AUTOSAR XML (schema 4-2-2)
package /AUTOLIV
  impl type au8MergedBuckleStatusType: category=ARRAY
    element elem_au8MergedBuckleStatusType_Appl: category=VALUE, array-size=6, array-size-semantics=FIXED-SIZE, base-type=uint8, data-constr=DataConstr_impl_u8GurtschlossStatusReihe2BFType_Appl
package /AUTOLIV/SoftwareCompositions/S32K_eCS_ECU_ApplicationComp
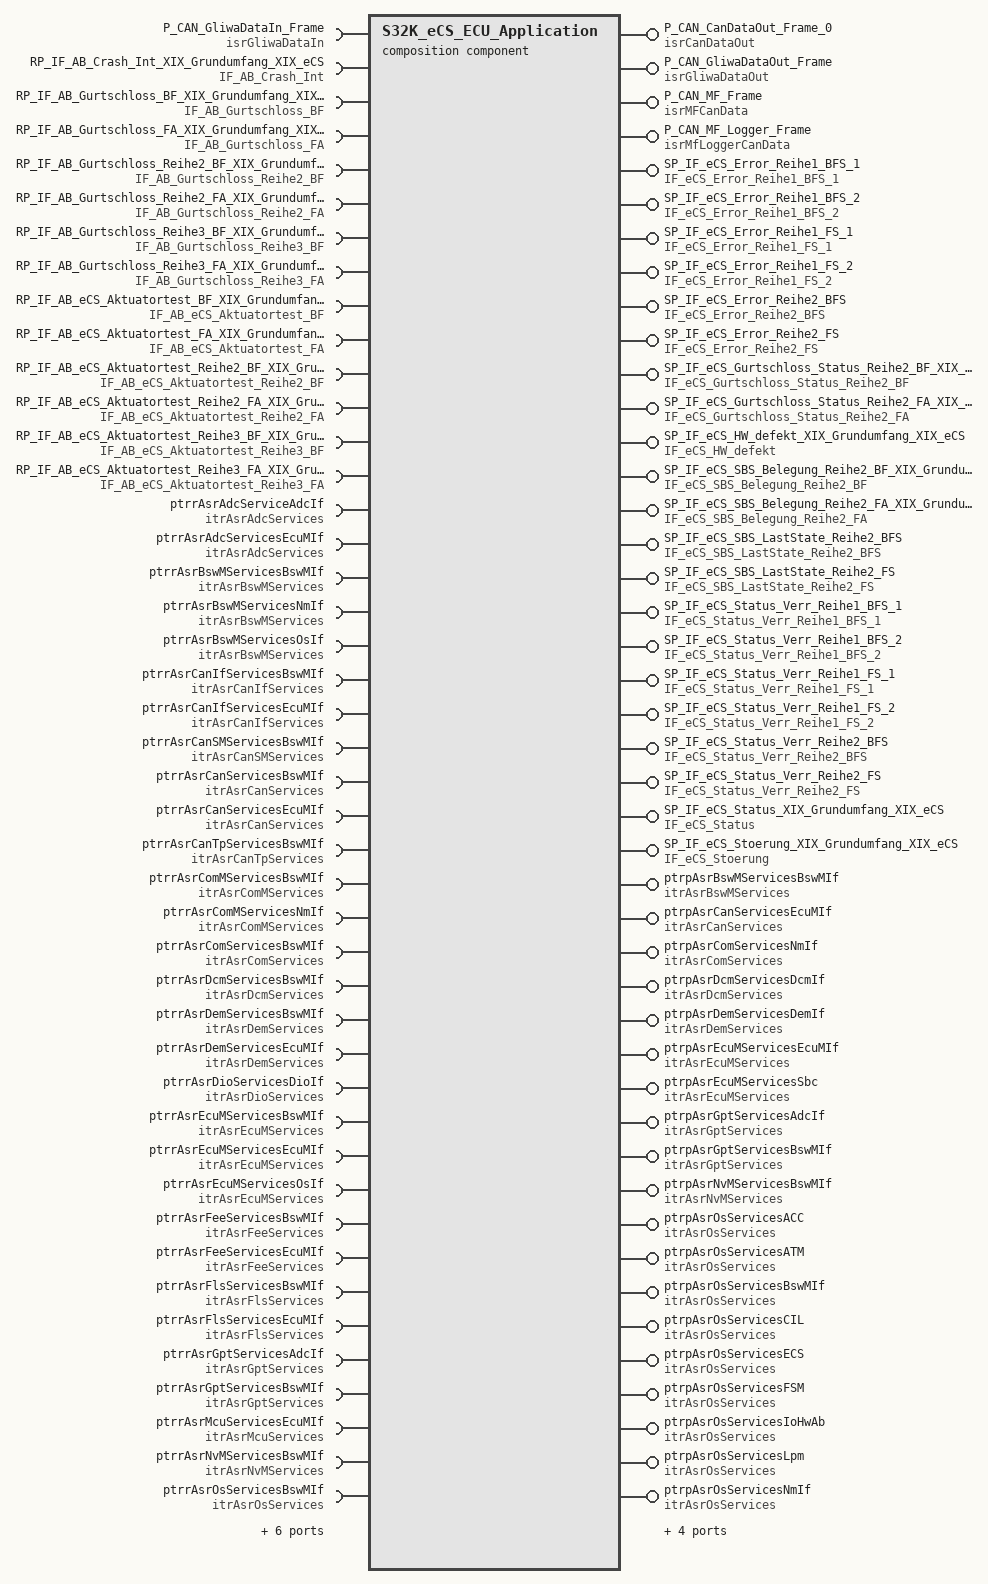
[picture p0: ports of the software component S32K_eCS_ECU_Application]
  composition sw component type S32K_eCS_ECU_Application
    provide port P_CAN_CanDataOut_Frame_0: provided-interface=isrCanDataOut
    require port P_CAN_GliwaDataIn_Frame: required-interface=isrGliwaDataIn
    provide port P_CAN_GliwaDataOut_Frame: provided-interface=isrGliwaDataOut
    provide port P_CAN_MF_Frame: provided-interface=isrMFCanData
    provide port P_CAN_MF_Logger_Frame: provided-interface=isrMfLoggerCanData
    13 x require port:
      RP_IF_AB_Crash_Int_XIX_Grundumfang_XIX_eCS: required-interface=IF_AB_Crash_Int
      RP_IF_AB_Gurtschloss_BF_XIX_Grundumfang_XIX_eCS: required-interface=IF_AB_Gurtschloss_BF
      RP_IF_AB_Gurtschloss_FA_XIX_Grundumfang_XIX_eCS: required-interface=IF_AB_Gurtschloss_FA
      RP_IF_AB_Gurtschloss_Reihe2_BF_XIX_Grundumfang_XIX_eCS: required-interface=IF_AB_Gurtschloss_Reihe2_BF
      RP_IF_AB_Gurtschloss_Reihe2_FA_XIX_Grundumfang_XIX_eCS: required-interface=IF_AB_Gurtschloss_Reihe2_FA
      RP_IF_AB_Gurtschloss_Reihe3_BF_XIX_Grundumfang_XIX_eCS: required-interface=IF_AB_Gurtschloss_Reihe3_BF
      RP_IF_AB_Gurtschloss_Reihe3_FA_XIX_Grundumfang_XIX_eCS: required-interface=IF_AB_Gurtschloss_Reihe3_FA
      RP_IF_AB_eCS_Aktuatortest_BF_XIX_Grundumfang_XIX_eCS: required-interface=IF_AB_eCS_Aktuatortest_BF
      RP_IF_AB_eCS_Aktuatortest_FA_XIX_Grundumfang_XIX_eCS: required-interface=IF_AB_eCS_Aktuatortest_FA
      RP_IF_AB_eCS_Aktuatortest_Reihe2_BF_XIX_Grundumfang_XIX_eCS: required-interface=IF_AB_eCS_Aktuatortest_Reihe2_BF
      RP_IF_AB_eCS_Aktuatortest_Reihe2_FA_XIX_Grundumfang_XIX_eCS: required-interface=IF_AB_eCS_Aktuatortest_Reihe2_FA
      RP_IF_AB_eCS_Aktuatortest_Reihe3_BF_XIX_Grundumfang_XIX_eCS: required-interface=IF_AB_eCS_Aktuatortest_Reihe3_BF
      RP_IF_AB_eCS_Aktuatortest_Reihe3_FA_XIX_Grundumfang_XIX_eCS: required-interface=IF_AB_eCS_Aktuatortest_Reihe3_FA
    44 x provide port:
      SP_IF_eCS_Error_Reihe1_BFS_1: provided-interface=IF_eCS_Error_Reihe1_BFS_1
      SP_IF_eCS_Error_Reihe1_BFS_2: provided-interface=IF_eCS_Error_Reihe1_BFS_2
      SP_IF_eCS_Error_Reihe1_FS_1: provided-interface=IF_eCS_Error_Reihe1_FS_1
      SP_IF_eCS_Error_Reihe1_FS_2: provided-interface=IF_eCS_Error_Reihe1_FS_2
      SP_IF_eCS_Error_Reihe2_BFS: provided-interface=IF_eCS_Error_Reihe2_BFS
      SP_IF_eCS_Error_Reihe2_FS: provided-interface=IF_eCS_Error_Reihe2_FS
      SP_IF_eCS_Gurtschloss_Status_Reihe2_BF_XIX_Grundumfang_XIX_eCS: provided-interface=IF_eCS_Gurtschloss_Status_Reihe2_BF
      SP_IF_eCS_Gurtschloss_Status_Reihe2_FA_XIX_Grundumfang_XIX_eCS: provided-interface=IF_eCS_Gurtschloss_Status_Reihe2_FA
      SP_IF_eCS_HW_defekt_XIX_Grundumfang_XIX_eCS: provided-interface=IF_eCS_HW_defekt
      SP_IF_eCS_SBS_Belegung_Reihe2_BF_XIX_Grundumfang_XIX_eCS: provided-interface=IF_eCS_SBS_Belegung_Reihe2_BF
      SP_IF_eCS_SBS_Belegung_Reihe2_FA_XIX_Grundumfang_XIX_eCS: provided-interface=IF_eCS_SBS_Belegung_Reihe2_FA
      SP_IF_eCS_SBS_LastState_Reihe2_BFS: provided-interface=IF_eCS_SBS_LastState_Reihe2_BFS
      SP_IF_eCS_SBS_LastState_Reihe2_FS: provided-interface=IF_eCS_SBS_LastState_Reihe2_FS
      SP_IF_eCS_Status_Verr_Reihe1_BFS_1: provided-interface=IF_eCS_Status_Verr_Reihe1_BFS_1
      SP_IF_eCS_Status_Verr_Reihe1_BFS_2: provided-interface=IF_eCS_Status_Verr_Reihe1_BFS_2
      SP_IF_eCS_Status_Verr_Reihe1_FS_1: provided-interface=IF_eCS_Status_Verr_Reihe1_FS_1
      SP_IF_eCS_Status_Verr_Reihe1_FS_2: provided-interface=IF_eCS_Status_Verr_Reihe1_FS_2
      SP_IF_eCS_Status_Verr_Reihe2_BFS: provided-interface=IF_eCS_Status_Verr_Reihe2_BFS
      SP_IF_eCS_Status_Verr_Reihe2_FS: provided-interface=IF_eCS_Status_Verr_Reihe2_FS
      SP_IF_eCS_Status_XIX_Grundumfang_XIX_eCS: provided-interface=IF_eCS_Status
      SP_IF_eCS_Stoerung_XIX_Grundumfang_XIX_eCS: provided-interface=IF_eCS_Stoerung
      ptrpAsrBswMServicesBswMIf: provided-interface=itrAsrBswMServices
      ptrpAsrCanServicesEcuMIf: provided-interface=itrAsrCanServices
      ptrpAsrComServicesNmIf: provided-interface=itrAsrComServices
      ptrpAsrDcmServicesDcmIf: provided-interface=itrAsrDcmServices
      ptrpAsrDemServicesDemIf: provided-interface=itrAsrDemServices
      ptrpAsrEcuMServicesEcuMIf: provided-interface=itrAsrEcuMServices
      ptrpAsrEcuMServicesSbc: provided-interface=itrAsrEcuMServices
      ptrpAsrGptServicesAdcIf: provided-interface=itrAsrGptServices
      ptrpAsrGptServicesBswMIf: provided-interface=itrAsrGptServices
      ptrpAsrNvMServicesBswMIf: provided-interface=itrAsrNvMServices
      ptrpAsrOsServicesACC: provided-interface=itrAsrOsServices
      ptrpAsrOsServicesATM: provided-interface=itrAsrOsServices
      ptrpAsrOsServicesBswMIf: provided-interface=itrAsrOsServices
      ptrpAsrOsServicesCIL: provided-interface=itrAsrOsServices
      ptrpAsrOsServicesECS: provided-interface=itrAsrOsServices
      ptrpAsrOsServicesFSM: provided-interface=itrAsrOsServices
      ptrpAsrOsServicesIoHwAb: provided-interface=itrAsrOsServices
      ptrpAsrOsServicesLpm: provided-interface=itrAsrOsServices
      ptrpAsrOsServicesNmIf: provided-interface=itrAsrOsServices
      ptrpAsrOsServicesOsIf: provided-interface=itrAsrOsServices
      ptrpAsrOsServicesSAD: provided-interface=itrAsrOsServices
      ptrpAsrOsServicesSBC: provided-interface=itrAsrOsServices
      ptrpAsrOsServicesSTM: provided-interface=itrAsrOsServices
    36 x require port:
      ptrrAsrAdcServiceAdcIf: required-interface=itrAsrAdcServices
      ptrrAsrAdcServicesEcuMIf: required-interface=itrAsrAdcServices
      ptrrAsrBswMServicesBswMIf: required-interface=itrAsrBswMServices
      ptrrAsrBswMServicesNmIf: required-interface=itrAsrBswMServices
      ptrrAsrBswMServicesOsIf: required-interface=itrAsrBswMServices
      ptrrAsrCanIfServicesBswMIf: required-interface=itrAsrCanIfServices
      ptrrAsrCanIfServicesEcuMIf: required-interface=itrAsrCanIfServices
      ptrrAsrCanSMServicesBswMIf: required-interface=itrAsrCanSMServices
      ptrrAsrCanServicesBswMIf: required-interface=itrAsrCanServices
      ptrrAsrCanServicesEcuMIf: required-interface=itrAsrCanServices
      ptrrAsrCanTpServicesBswMIf: required-interface=itrAsrCanTpServices
      ptrrAsrComMServicesBswMIf: required-interface=itrAsrComMServices
      ptrrAsrComMServicesNmIf: required-interface=itrAsrComMServices
      ptrrAsrComServicesBswMIf: required-interface=itrAsrComServices
      ptrrAsrDcmServicesBswMIf: required-interface=itrAsrDcmServices
      ptrrAsrDemServicesBswMIf: required-interface=itrAsrDemServices
      ptrrAsrDemServicesEcuMIf: required-interface=itrAsrDemServices
      ptrrAsrDioServicesDioIf: required-interface=itrAsrDioServices
      ptrrAsrEcuMServicesBswMIf: required-interface=itrAsrEcuMServices
      ptrrAsrEcuMServicesEcuMIf: required-interface=itrAsrEcuMServices
      ptrrAsrEcuMServicesOsIf: required-interface=itrAsrEcuMServices
      ptrrAsrFeeServicesBswMIf: required-interface=itrAsrFeeServices
      ptrrAsrFeeServicesEcuMIf: required-interface=itrAsrFeeServices
      ptrrAsrFlsServicesBswMIf: required-interface=itrAsrFlsServices
      ptrrAsrFlsServicesEcuMIf: required-interface=itrAsrFlsServices
      ptrrAsrGptServicesAdcIf: required-interface=itrAsrGptServices
      ptrrAsrGptServicesBswMIf: required-interface=itrAsrGptServices
      ptrrAsrMcuServicesEcuMIf: required-interface=itrAsrMcuServices
      ptrrAsrNvMServicesBswMIf: required-interface=itrAsrNvMServices
      ptrrAsrOsServicesBswMIf: required-interface=itrAsrOsServices
      ptrrAsrPduRServicesBswMIf: required-interface=itrAsrPduRServices
      ptrrAsrPwmServicesEcuMIf: required-interface=itrAsrPwmServices
      ptrrAsrPwmServicesPwmIf: required-interface=itrAsrPwmServices
      ptrrAsrRteServicesBswMIf: required-interface=itrAsrRteServices
      ptrrAsrSpiServicesEcuMIf: required-interface=itrAsrSpiServices
      ptrrAsrSpiServicesSpiIf: required-interface=itrAsrSpiServices
    29 x component:
      ACC: type=ACC
      ATM: type=ATM
      AdcIf: type=AdcIf
      BswMIf: type=BswMIf
      CIL: type=CIL
      DIA: type=DIA
      DcmIf: type=DcmIf
      DemIf: type=DemIf
      DioIf: type=DioIf
      EFX: type=EFX
      EIM: type=EIM
      EcuMIf: type=EcuMIf
      FSM: type=FSM
      IoHwAb: type=IoHwAb
      LPM: type=LPM
      MIC: type=MIC
      McuIf: type=McuIf
      NVP: type=NVP
      NmIf: type=NmIf
      NvmIf: type=NvmIf
      OsIf: type=OsIf
      PwmIf: type=PwmIf
      RCM: type=RCM
      SAD: type=SAD
      SBC: type=SBC
      STM: type=STM
      SpiIf: type=SpiIf
      T1: type=T1
      eCS: type=eCS
    connectors delegation-sw-connector={inner-port=ATM.ptrpAtmServicesAsrOs, outer-port=ptrpAsrOsServicesATM}, delegation-sw-connector={inner-port=BswMIf.ptrrAsrBswMServicesBswMIf, outer-port=S32K_eCS_ECU_Application/ptrrAsrBswMServicesBswMIf}, delegation-sw-connector={inner-port=BswMIf.ptrpAsrBswMServicesBswMIf, outer-port=S32K_eCS_ECU_Application/ptrpAsrBswMServicesBswMIf}, delegation-sw-connector={inner-port=BswMIf.ptrpAsrGptServicesBswMIf, outer-port=S32K_eCS_ECU_Application/ptrpAsrGptServicesBswMIf}, delegation-sw-connector={inner-port=BswMIf.ptrpAsrOsServicesBswMIf, outer-port=S32K_eCS_ECU_Application/ptrpAsrOsServicesBswMIf}, delegation-sw-connector={inner-port=BswMIf.ptrrAsrEcuMServicesBswMIf, outer-port=ptrrAsrEcuMServicesBswMIf}, delegation-sw-connector={inner-port=BswMIf.ptrrAsrGptServicesBswMIf, outer-port=S32K_eCS_ECU_Application/ptrrAsrGptServicesBswMIf}, delegation-sw-connector={inner-port=AdcIf.ptrrAsrAdcServicesAdcIf, outer-port=ptrrAsrAdcServiceAdcIf}, delegation-sw-connector={inner-port=AdcIf.ptrrAsrGptServicesAdcIf, outer-port=S32K_eCS_ECU_Application/ptrrAsrGptServicesAdcIf}, delegation-sw-connector={inner-port=AdcIf.ptrpAsrGptServicesAdcIf, outer-port=S32K_eCS_ECU_Application/ptrpAsrGptServicesAdcIf}, delegation-sw-connector={inner-port=CIL.P_CAN_GliwaDataIn_Frame, outer-port=P_CAN_GliwaDataIn_Frame}, delegation-sw-connector={inner-port=CIL.RP_IF_AB_Crash_Int_XIX_Grundumfang_XIX_eCS, outer-port=RP_IF_AB_Crash_Int_XIX_Grundumfang_XIX_eCS}, delegation-sw-connector={inner-port=CIL.RP_IF_AB_Gurtschloss_BF_XIX_Grundumfang_XIX_eCS, outer-port=RP_IF_AB_Gurtschloss_BF_XIX_Grundumfang_XIX_eCS}, delegation-sw-connector={inner-port=CIL.RP_IF_AB_Gurtschloss_FA_XIX_Grundumfang_XIX_eCS, outer-port=RP_IF_AB_Gurtschloss_FA_XIX_Grundumfang_XIX_eCS}, delegation-sw-connector={inner-port=CIL.RP_IF_AB_Gurtschloss_Reihe2_BF_XIX_Grundumfang_XIX_eCS, outer-port=RP_IF_AB_Gurtschloss_Reihe2_BF_XIX_Grundumfang_XIX_eCS}, delegation-sw-connector={inner-port=CIL.RP_IF_AB_Gurtschloss_Reihe2_FA_XIX_Grundumfang_XIX_eCS, outer-port=RP_IF_AB_Gurtschloss_Reihe2_FA_XIX_Grundumfang_XIX_eCS}, delegation-sw-connector={inner-port=CIL.RP_IF_AB_Gurtschloss_Reihe3_BF_XIX_Grundumfang_XIX_eCS, outer-port=RP_IF_AB_Gurtschloss_Reihe3_BF_XIX_Grundumfang_XIX_eCS}, delegation-sw-connector={inner-port=CIL.RP_IF_AB_Gurtschloss_Reihe3_FA_XIX_Grundumfang_XIX_eCS, outer-port=RP_IF_AB_Gurtschloss_Reihe3_FA_XIX_Grundumfang_XIX_eCS}, delegation-sw-connector={inner-port=CIL.RP_IF_AB_eCS_Aktuatortest_BF_XIX_Grundumfang_XIX_eCS, outer-port=RP_IF_AB_eCS_Aktuatortest_BF_XIX_Grundumfang_XIX_eCS}, delegation-sw-connector={inner-port=CIL.RP_IF_AB_eCS_Aktuatortest_FA_XIX_Grundumfang_XIX_eCS, outer-port=RP_IF_AB_eCS_Aktuatortest_FA_XIX_Grundumfang_XIX_eCS}, delegation-sw-connector={inner-port=CIL.RP_IF_AB_eCS_Aktuatortest_Reihe2_BF_XIX_Grundumfang_XIX_eCS, outer-port=RP_IF_AB_eCS_Aktuatortest_Reihe2_BF_XIX_Grundumfang_XIX_eCS}, delegation-sw-connector={inner-port=CIL.RP_IF_AB_eCS_Aktuatortest_Reihe2_FA_XIX_Grundumfang_XIX_eCS, outer-port=RP_IF_AB_eCS_Aktuatortest_Reihe2_FA_XIX_Grundumfang_XIX_eCS}, delegation-sw-connector={inner-port=CIL.RP_IF_AB_eCS_Aktuatortest_Reihe3_BF_XIX_Grundumfang_XIX_eCS, outer-port=RP_IF_AB_eCS_Aktuatortest_Reihe3_BF_XIX_Grundumfang_XIX_eCS}, delegation-sw-connector={inner-port=CIL.RP_IF_AB_eCS_Aktuatortest_Reihe3_FA_XIX_Grundumfang_XIX_eCS, outer-port=RP_IF_AB_eCS_Aktuatortest_Reihe3_FA_XIX_Grundumfang_XIX_eCS}, delegation-sw-connector={inner-port=CIL.P_CAN_GliwaDataOut_Frame, outer-port=P_CAN_GliwaDataOut_Frame}, delegation-sw-connector={inner-port=CIL.SP_IF_eCS_Gurtschloss_Status_Reihe2_BF_XIX_Grundumfang_XIX_eCS, outer-port=SP_IF_eCS_Gurtschloss_Status_Reihe2_BF_XIX_Grundumfang_XIX_eCS}, delegation-sw-connector={inner-port=CIL.SP_IF_eCS_Gurtschloss_Status_Reihe2_FA_XIX_Grundumfang_XIX_eCS, outer-port=SP_IF_eCS_Gurtschloss_Status_Reihe2_FA_XIX_Grundumfang_XIX_eCS}, delegation-sw-connector={inner-port=CIL.SP_IF_eCS_HW_defekt_XIX_Grundumfang_XIX_eCS, outer-port=SP_IF_eCS_HW_defekt_XIX_Grundumfang_XIX_eCS}, delegation-sw-connector={inner-port=CIL.SP_IF_eCS_SBS_Belegung_Reihe2_BF_XIX_Grundumfang_XIX_eCS, outer-port=SP_IF_eCS_SBS_Belegung_Reihe2_BF_XIX_Grundumfang_XIX_eCS}, delegation-sw-connector={inner-port=CIL.SP_IF_eCS_SBS_Belegung_Reihe2_FA_XIX_Grundumfang_XIX_eCS, outer-port=SP_IF_eCS_SBS_Belegung_Reihe2_FA_XIX_Grundumfang_XIX_eCS}, delegation-sw-connector={inner-port=CIL.SP_IF_eCS_Status_XIX_Grundumfang_XIX_eCS, outer-port=SP_IF_eCS_Status_XIX_Grundumfang_XIX_eCS}, delegation-sw-connector={inner-port=CIL.SP_IF_eCS_Stoerung_XIX_Grundumfang_XIX_eCS, outer-port=SP_IF_eCS_Stoerung_XIX_Grundumfang_XIX_eCS}, delegation-sw-connector={inner-port=EcuMIf.ptrrAsrAdcServicesEcuMIf, outer-port=ptrrAsrAdcServicesEcuMIf}, delegation-sw-connector={inner-port=EcuMIf.ptrrAsrCanIfServicesEcuMIf, outer-port=ptrrAsrCanIfServicesEcuMIf}, delegation-sw-connector={inner-port=EcuMIf.ptrrAsrCanServicesEcuMIf, outer-port=S32K_eCS_ECU_Application/ptrrAsrCanServicesEcuMIf}, delegation-sw-connector={inner-port=EcuMIf.ptrrAsrDemServicesEcuMIf, outer-port=ptrrAsrDemServicesEcuMIf}, delegation-sw-connector={inner-port=EcuMIf.ptrrAsrEcuMServicesEcuMIf, outer-port=S32K_eCS_ECU_Application/ptrrAsrEcuMServicesEcuMIf}, delegation-sw-connector={inner-port=EcuMIf.ptrrAsrFeeServicesEcuMIf, outer-port=ptrrAsrFeeServicesEcuMIf}, delegation-sw-connector={inner-port=EcuMIf.ptrrAsrFlsServicesEcuMIf, outer-port=ptrrAsrFlsServicesEcuMIf}, delegation-sw-connector={inner-port=EcuMIf.ptrrAsrPwmServicesEcuMIf, outer-port=ptrrAsrPwmServicesEcuMIf}, delegation-sw-connector={inner-port=EcuMIf.ptrrSpiServicesEcuMIf, outer-port=ptrrAsrSpiServicesEcuMIf}, delegation-sw-connector={inner-port=EcuMIf.ptrpAsrCanServicesEcuMIf, outer-port=S32K_eCS_ECU_Application/ptrpAsrCanServicesEcuMIf}, delegation-sw-connector={inner-port=EcuMIf.ptrpAsrEcuMServicesEcuMIf, outer-port=S32K_eCS_ECU_Application/ptrpAsrEcuMServicesEcuMIf}, delegation-sw-connector={inner-port=DcmIf.ptrpAsrDcmServicesDcmIf, outer-port=ptrpAsrDcmServicesDcmIf}, delegation-sw-connector={inner-port=IoHwAb.ptrpAsrOsServicesIoHwAb, outer-port=ptrpAsrOsServicesIoHwAb}, delegation-sw-connector={inner-port=LPM.ptrpLpmServicesAsrOs, outer-port=ptrpAsrOsServicesLpm}, delegation-sw-connector={inner-port=OsIf.ptrrAsrBswMServicesOsIf, outer-port=ptrrAsrBswMServicesOsIf}, delegation-sw-connector={inner-port=OsIf.ptrrAsrEcuMServicesOsIf, outer-port=ptrrAsrEcuMServicesOsIf}, delegation-sw-connector={inner-port=NmIf.ptrrAsrBswMServicesNmIf, outer-port=ptrrAsrBswMServicesNmIf}, delegation-sw-connector={inner-port=NmIf.ptrrAsrComMServicesNmIf, outer-port=ptrrAsrComMServicesNmIf}, delegation-sw-connector={inner-port=NmIf.ptrpAsrComServicesNmIf, outer-port=ptrpAsrComServicesNmIf}, delegation-sw-connector={inner-port=NmIf.ptrpAsrOsServicesNmIf, outer-port=ptrpAsrOsServicesNmIf}, delegation-sw-connector={inner-port=PwmIf.ptrrAsrPwmServicesPwmIf, outer-port=ptrrAsrPwmServicesPwmIf}, delegation-sw-connector={inner-port=SBC.ptrpSbcServicesEcuM, outer-port=ptrpAsrEcuMServicesSbc}, delegation-sw-connector={inner-port=SpiIf.ptrrAsrSpiServicesSpiIf, outer-port=ptrrAsrSpiServicesSpiIf}, delegation-sw-connector={inner-port=DemIf.ptrpAsrDemServicesDemIf, outer-port=ptrpAsrDemServicesDemIf}, delegation-sw-connector={inner-port=CIL.SP_IF_eCS_Error_Reihe1_BFS_1, outer-port=SP_IF_eCS_Error_Reihe1_BFS_1}, delegation-sw-connector={inner-port=CIL.SP_IF_eCS_Error_Reihe1_BFS_2, outer-port=SP_IF_eCS_Error_Reihe1_BFS_2}, delegation-sw-connector={inner-port=CIL.SP_IF_eCS_Error_Reihe1_FS_1, outer-port=SP_IF_eCS_Error_Reihe1_FS_1}, delegation-sw-connector={inner-port=CIL.SP_IF_eCS_Error_Reihe1_FS_2, outer-port=SP_IF_eCS_Error_Reihe1_FS_2}, delegation-sw-connector={inner-port=CIL.SP_IF_eCS_Error_Reihe2_BFS, outer-port=SP_IF_eCS_Error_Reihe2_BFS}, delegation-sw-connector={inner-port=CIL.SP_IF_eCS_Error_Reihe2_FS, outer-port=SP_IF_eCS_Error_Reihe2_FS}, delegation-sw-connector={inner-port=CIL.SP_IF_eCS_SBS_LastState_Reihe2_BFS, outer-port=SP_IF_eCS_SBS_LastState_Reihe2_BFS}, delegation-sw-connector={inner-port=CIL.SP_IF_eCS_SBS_LastState_Reihe2_FS, outer-port=SP_IF_eCS_SBS_LastState_Reihe2_FS}, delegation-sw-connector={inner-port=CIL.SP_IF_eCS_Status_Verr_Reihe1_BFS_1, outer-port=SP_IF_eCS_Status_Verr_Reihe1_BFS_1}, delegation-sw-connector={inner-port=CIL.SP_IF_eCS_Status_Verr_Reihe1_BFS_2, outer-port=SP_IF_eCS_Status_Verr_Reihe1_BFS_2}, delegation-sw-connector={inner-port=CIL.SP_IF_eCS_Status_Verr_Reihe1_FS_1, outer-port=SP_IF_eCS_Status_Verr_Reihe1_FS_1}, delegation-sw-connector={inner-port=CIL.SP_IF_eCS_Status_Verr_Reihe1_FS_2, outer-port=SP_IF_eCS_Status_Verr_Reihe1_FS_2}, delegation-sw-connector={inner-port=CIL.SP_IF_eCS_Status_Verr_Reihe2_BFS, outer-port=SP_IF_eCS_Status_Verr_Reihe2_BFS}, delegation-sw-connector={inner-port=CIL.SP_IF_eCS_Status_Verr_Reihe2_FS, outer-port=SP_IF_eCS_Status_Verr_Reihe2_FS}:
      connect ACC.pseAccRestartInit -> LPM.pclAccRestartInit
      connect ACC.pseCheckAccAlarmbPin -> ATM.pclCheckAccAlarmbPin
      connect ACC.psr3DAcceleration -> CIL.prr3DAcceleration
      connect ACC.psr3DAcceleration -> DIA.prr3DAcceleration
      connect ACC.psrACCServices -> FSM.prrACCServices
      connect ACC.psrAccStatusFailiureSource -> CIL.prrAccStatusFailiureSource
      connect ACC.psrAccelMtrPerSecSqd -> CIL.prrAccelMtrPerSecSqd
      connect ACC.psrAccelMtrPerSecSqd -> eCS.prrAccelMtrPerSecSqd
      connect ACC.pseAccTemperatureSpiData -> IoHwAb.pclAccSpiData
      delegate ACC.ptrpAsrOsServicesACC <-> outer port ptrpAsrOsServicesACC
      connect ATM.pseAutotestServices -> FSM.pclAutotestServices
      connect ATM.pseAutotestServices -> IoHwAb.pclAutotestServices
      connect ATM.pseAutotestServices -> SAD.pclAutotestServices
      connect ATM.ptrpAtmServicesBswMIf -> BswMIf.ptrrAtmServicesBswMIf
      connect AdcIf.prrAdcBufferServices -> IoHwAb.prrAdcBufferServices
      connect AdcIf.pseAdcIfServices -> LPM.pclAdcIfServices
      connect AdcIf.ptrpAdcIfServicesBswMIf -> BswMIf.ptrrAdcIfServicesBswMIf
      connect AdcIf.ptrpEcuMIfServicesAdcIf -> EcuMIf.ptrrEcuMIfServicesAdcIf
      connect AdcIf.pseRawAdcService -> IoHwAb.pclRawAdcService
      connect BswMIf.pseEcuStateTransitions -> NmIf.pclEcuStateTransitionBswMIf
      connect BswMIf.psePassengerOccupancyState -> IoHwAb.pclPassengerOccupancyState
      connect BswMIf.psrBswMIfServices -> FSM.prrBswMIfServices
      connect BswMIf.psrFsmSolenoidReqBswMIf -> FSM.prrEcsDiagRequest
      connect BswMIf.ptrpNmIfServicesBswMIf -> NmIf.ptrrNmIfServicesBswMIf
      connect CIL.pseSetEcuStateSignal -> BswMIf.pclCILGetEcuState
      connect CIL.psrCILData -> FSM.prrCILData
      connect CIL.psrCrashStatus -> FSM.prrCrashStatus
      connect CIL.psrEcsDiagRequest -> FSM.prrEcsDiagRequest
      delegate CIL.ptrpAsrOsServicesCIL <-> outer port ptrpAsrOsServicesCIL
      connect CIL.ptrpCilServicesBswMIf -> BswMIf.ptrrCilServicesBswMIf
      connect DIA.pseEcsDiagRequest -> FSM.prrEcsDiagRequest
      connect DIA.ptrpDiaServicesBswMIf -> BswMIf.ptrrDiaServicesBswMIf
      connect DemIf.pseDemIfEventServices -> FSM.pclDemIfEventSerices
      connect DioIf.psrDioIfServices -> ACC.pclDioIfServices
      connect DioIf.psrDioIfServices -> IoHwAb.pclDioIfServices
      connect DioIf.ptrpEcuMIfServicesDioIf -> EcuMIf.ptrrEcuMIfServicesDioIf
      connect AdcIf.pseCheckAdcCalib -> ATM.pclCheckAdcCalib
      connect AdcIf.pseCheckAdc -> ATM.pclCheckAdc
      connect NvmIf.pseNvmIfServices -> DIA.pclNvmIfServices
      connect PwmIf.psePwmServices -> SAD.pclPwmServices
      connect RCM.pseResetCause -> DIA.pclResetCause
      connect MIC.pseRunEepromMemoryCorruption -> ATM.pclRunEepromMemoryCorruption
      connect NvmIf.pseRunEepromMemoryNotProgrammed -> ATM.pclRunEepromMemoryNotProgrammed
      connect MIC.pseRunPFlashMemoryCorruption -> ATM.pclRunPFlashMemoryCorruption
      connect MIC.pseRunRamMemoryCorruption -> ATM.pclRunRamMemoryCorruption
      connect RCM.pseRunResetCause -> ATM.pclRunResetCause
      connect DioIf.psrDioIfServices -> SAD.pclDioIfServices
      connect EFX.pseEfxServices -> IoHwAb.pclEfxServices
      connect EIM.pseInjectError -> ATM.pclInjectError
      connect FSM.pseFsmServices -> DIA.pclFsmServices
      connect FSM.pseModeManagement -> ATM.pclModeManagement
      connect FSM.pseModeManagement -> CIL.pclModeManagement
      connect FSM.pseModeManagement -> IoHwAb.pclModeManagement
      connect FSM.pseModeManagement -> SAD.pclModeManagement
      connect FSM.pseModeManagement -> eCS.pclModeManagement
      connect FSM.pseFsmServices -> IoHwAb.pclUnlockTimeout
      connect FSM.psrSolenoidProfile -> SAD.prrSolenoidProfile
      connect FSM.psrSolenoidStuckStatus -> CIL.prrSolenoidStuckStatus
      connect FSM.psrSolenoidStuckStatus -> SAD.prrSolenoidStuckStatus
      connect FSM.psrSolenoidProfile -> ACC.prrSolenoidProfile
      connect FSM.psrSolenoidProfile -> CIL.pclSolenoidProfile
      connect FSM.psrSolenoidProfile -> EIM.prrFSMSolenoidProfile
      connect FSM.psrSolenoidProfile -> IoHwAb.pclSolenoidProfile
      connect FSM.psrSolenoidState -> CIL.prrSolenoidState
      connect FSM.psrSolenoidState -> SAD.prrSolenoidState
      delegate FSM.ptrpAsrOsServicesFSM <-> outer port ptrpAsrOsServicesFSM
      connect FSM.ptrpFsmServicesBswMIf -> BswMIf.ptrrFsmServicesBswMIf
      connect IoHwAb.pseAccSensor -> CIL.pclAccSensor
      connect IoHwAb.pseAccSensor -> DIA.pclAccSensor
      connect IoHwAb.pseCheckPowerSupplyOV -> ATM.pclCheckPowerSupplyOV
      connect IoHwAb.pseCheckPowerSupplyUV -> ATM.pclCheckPowerSupplyUV
      connect IoHwAb.pseConvAdcService -> FSM.pclConvAdcService
      connect IoHwAb.pseConvAdcService -> SAD.pclConvAdcService
      connect IoHwAb.pseEcuCharacteristics -> CIL.pclEcuCharacterstics
      connect IoHwAb.pseEcuOverTemperature -> ATM.pclEcuOverTemperature
      connect IoHwAb.pseHandleSeatCurrentCircuit -> LPM.pclHandleSeatCurrentCircuit
      connect IoHwAb.pseConvAdcService -> CIL.pclConvAdcService
      connect IoHwAb.pseConvAdcService -> DIA.pclConvAdcService
      connect IoHwAb.pseLowPowerWakeUp -> LPM.pclLowPowerWakeUp
      connect IoHwAb.pseMcuCharacteristics -> CIL.pclMcuCharacteristics
      connect IoHwAb.pseMcuCharacteristics -> DIA.pclMcuCharacteristics
      connect IoHwAb.pseEcuCharacteristics -> DIA.pclEcuCharacterstics
      connect IoHwAb.psePtcSensor -> CIL.pclPtcSensor
      connect IoHwAb.psePtcSensor -> DIA.pclPtcSensor
      connect IoHwAb.pseSolenoidCharacterstics -> CIL.pclSolenoidCharacteristics
      connect IoHwAb.psrBuckleStatus -> CIL.prrBuckleStatus
      connect IoHwAb.psrSeatOccupancySensorStatus -> CIL.prrSeatOccupancySensorStatus
      connect IoHwAb.psrSolenoidConfirmation -> FSM.prrSolenoidConfirmation
      connect LPM.ptrpLpmServicesBswMIf -> BswMIf.ptrrLpmServicesBswMIf
      connect MIC.p_ptrrMicServicesBswMIf -> BswMIf.ptrrMicServices
      connect MIC.p_ptrrMicServicesOsIf -> OsIf.ptrrMicServices
      connect McuIf.pseCheckCrcOnMcuRegisters -> ATM.pclCheckCrcOnMcuRegisters
      connect McuIf.pseCheckMcuSelfTest -> ATM.pclCheckMcuSelfTest
      connect McuIf.ptrpMcuIfServicesBswmIf -> BswMIf.ptrrMcuIfServicesBswMIf
      connect NVP.pseNvpBlockDataDia -> DIA.pseNvpBlockData
      connect NVP.pseNvpBlockDataDcmIf -> DcmIf.pseNvpBlockData
      connect NvmIf.pseNvmIfServices -> BswMIf.pclNvmIfServices
      connect NvmIf.pseNvmIfServices -> DcmIf.pclNvmIfServices
      connect NvmIf.pseNvmIfServices -> FSM.pclNvmIfServices
      connect NvmIf.pseNvmIfServices -> IoHwAb.pclNvmIfServices
      connect NvmIf.pseNvmIfServices -> MIC.pclNvmIfServices
      connect NvmIf.pseNvmIfServices -> RCM.pclNvmIfServices
      delegate OsIf.ptrpAsrOsServicesOsIf <-> outer port ptrpAsrOsServicesOsIf
      connect RCM.pseOSErrorReport -> OsIf.pclRcmServices
      connect RCM.pseResetCauseNotification -> BswMIf.pclNotifyResetCause
      connect RCM.pseResetCauseNotification -> DIA.pclResetCauseNotification
      connect RCM.pseResetCauseNotification -> EcuMIf.pclNotifyResetCause
      connect RCM.pseResetCauseNotification -> MIC.pclResetCauseNotification
      connect RCM.pseResetCauseNotification -> OsIf.pclResetCauseNotification
      connect RCM.pseResetCauseNotification -> SBC.pclResetCauseNotification
      connect RCM.pseResetCause -> MIC.pclResetCause
      connect RCM.pseResetCause -> SBC.pclResetCause
      connect RCM.ptrpRcmServicesBswMIf -> BswMIf.ptrrRcmServicesBswMIf
      connect SAD.pseCheckActuatorState -> ATM.pclCheckActuatorState
      connect SAD.pseCheckPowerStage -> ATM.pclCheckPowerStage
      connect SAD.pseCheckSolenoidOpenCircuit -> ATM.pclCheckOpenCircuit
      connect SAD.pseCheckSolenoidOvervoltage -> ATM.pclCheckSolenoidOvervoltage
      connect SAD.pseCheckSolenoidShortToGND -> ATM.pclCheckShortToGND
      connect SAD.pseCheckSolenoidShortToVBAT -> ATM.pclCheckShortToVBAT
      connect SAD.pseDiagRequestServices -> FSM.prrEcsDiagRequest
      connect SAD.pseSolenoidPWM -> CIL.prrSolenoidPWM
      connect SAD.pseSolenoidPWM -> IoHwAb.prrSolenoidPwm
      connect SAD.pseSolenoidStep -> CIL.pclSolenoidStep
      connect SAD.pseSolenoidStep -> IoHwAb.pclSolenoidStep
      connect SAD.psrSolenoidElectricalCharacteristics -> IoHwAb.prrSolenoidElectricalCharacteristics
      connect SAD.psrSolenoidOpenCircutStatus -> CIL.prrSolenoidOCStatus
      connect SAD.psrSolenoidOpenCircutStatus -> FSM.prrSolenoidOpenCircuitStatus
      connect SAD.psrSolenoidOvervoltageStatus -> CIL.prrSolenoidOvervoltageStatus
      connect SAD.psrSolenoidOvervoltageStatus -> FSM.prrSolenoidOverVoltageStatus
      connect SAD.psrSolenoidShortToGndStatus -> CIL.prrSolenoidShortToGndStatus
      connect SAD.psrSolenoidShortToGndStatus -> FSM.prrSolenoidShortToGndStatus
      connect SAD.psrSolenoidShortToVccStatus -> CIL.prrSolenoidShortToVccStatus
      delegate SAD.ptrpAsrOsServicesSAD <-> outer port ptrpAsrOsServicesSAD
      connect SAD.ptrpSadServicesBswMIf -> BswMIf.ptrrSadServicesBswMIf
      connect SBC.pseCheckSbcStatusInfo -> ATM.pclCheckSbcStatusInfo
      connect SBC.pseSbcServices -> LPM.pclSbcServices
      connect SBC.pseSbcStatus -> EcuMIf.pclSbcServices
      connect SBC.pseSbcStatus -> MIC.pclSbcServices
      connect SBC.pseSbcStatus -> RCM.pclSbcWdgServices
      connect SBC.pseSbcWdgAutotest -> ATM.pclRunExtWDTest
      connect SBC.psrSbcStatusFailiureSource -> CIL.prrSbcStatusFailiureSource
      delegate SBC.ptrpAsrOsServicesSBC <-> outer port ptrpAsrOsServicesSBC
      connect STM.pseSystemTime -> DIA.pclSystemTime
      delegate STM.ptrpAsrOsServicesSTM <-> outer port ptrpAsrOsServicesSTM
      connect SpiIf.ptrpSpiIfServicesACC -> ACC.ptrrSpiIfServices
      connect SpiIf.ptrpSpiIfServicesSBC -> SBC.ptrrSpiIfServices
      connect eCS.psrEcsAlgoData -> CIL.prrEcsAlgoData
      connect eCS.psrEcsAlgoData -> FSM.prrEcsAlgoFlag
      delegate eCS.ptrpAsrOsServicesECS <-> outer port ptrpAsrOsServicesECS
      delegate BswMIf.ptrrAsrCanIfServicesBswMIf <-> outer port ptrrAsrCanIfServicesBswMIf
      delegate BswMIf.ptrrAsrCanSMServicesBswMIf <-> outer port ptrrAsrCanSMServicesBswMIf
      delegate BswMIf.ptrrAsrCanServicesBswMIf <-> outer port ptrrAsrCanServicesBswMIf
      delegate BswMIf.ptrrAsrCanTpServicesBswMIf <-> outer port ptrrAsrCanTpServicesBswMIf
      delegate BswMIf.ptrrAsrComServicesBswMIf <-> outer port ptrrAsrComServicesBswMIf
      delegate BswMIf.ptrrAsrNvMServicesBswMIf <-> outer port S32K_eCS_ECU_Application/ptrrAsrNvMServicesBswMIf
      delegate BswMIf.ptrrAsrOsServicesBswMIf <-> outer port S32K_eCS_ECU_Application/ptrrAsrOsServicesBswMIf
      delegate BswMIf.ptrrAsrPduRServicesBswMIf <-> outer port ptrrAsrPduRServicesBswMIf
      delegate BswMIf.ptrpAsrNvMServicesBswMIf <-> outer port S32K_eCS_ECU_Application/ptrpAsrNvMServicesBswMIf
      delegate BswMIf.ptrrAsrComMServicesBswMIf <-> outer port ptrrAsrComMServicesBswMIf
      delegate BswMIf.ptrrAsrDcmServicesBswMIf <-> outer port ptrrAsrDcmServicesBswMIf
      delegate BswMIf.ptrrAsrDemServicesBswMIf <-> outer port ptrrAsrDemServicesBswMIf
      delegate BswMIf.ptrrAsrRteServicesBswMIf <-> outer port ptrrAsrRteServicesBswMIf
      delegate BswMIf.ptrrAsrFeeServicesBswMIf <-> outer port ptrrAsrFeeServicesBswMIf
      delegate BswMIf.ptrrAsrFlsServicesBswMIf <-> outer port ptrrAsrFlsServicesBswMIf
      delegate DioIf.ptrrAsrDioServicesDioIf <-> outer port ptrrAsrDioServicesDioIf
      delegate EcuMIf.ptrrAsrMcuServicesEcuMIf <-> outer port ptrrAsrMcuServicesEcuMIf
      delegate CIL.P_CAN_MF_Frame <-> outer port P_CAN_MF_Frame
      delegate CIL.P_CAN_MF_Logger_Frame <-> outer port P_CAN_MF_Logger_Frame
      delegate CIL.P_CAN_CanDataOut_Frame_0 <-> outer port P_CAN_CanDataOut_Frame_0
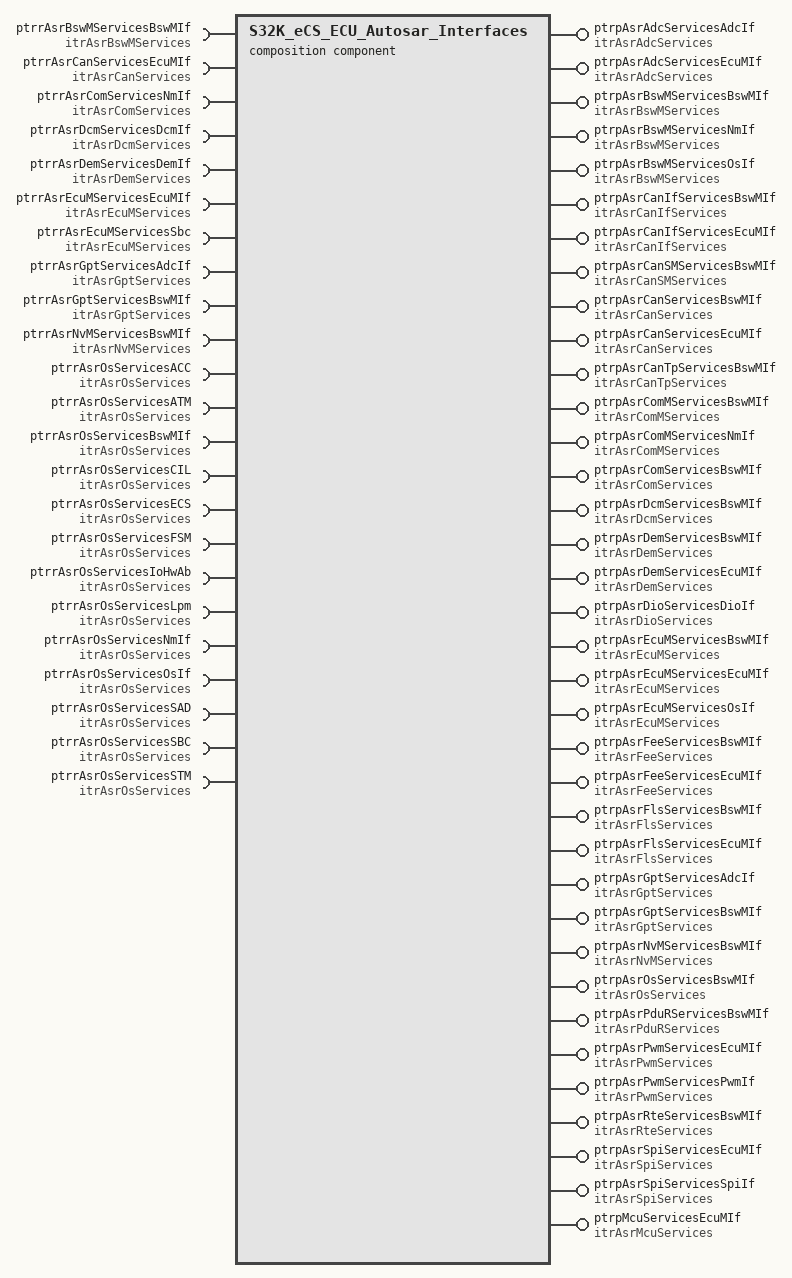
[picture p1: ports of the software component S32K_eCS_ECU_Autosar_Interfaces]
  composition sw component type S32K_eCS_ECU_Autosar_Interfaces
    36 x provide port:
      ptrpAsrAdcServicesAdcIf: provided-interface=itrAsrAdcServices
      ptrpAsrAdcServicesEcuMIf: provided-interface=itrAsrAdcServices
      ptrpAsrBswMServicesBswMIf: provided-interface=itrAsrBswMServices
      ptrpAsrBswMServicesNmIf: provided-interface=itrAsrBswMServices
      ptrpAsrBswMServicesOsIf: provided-interface=itrAsrBswMServices
      ptrpAsrCanIfServicesBswMIf: provided-interface=itrAsrCanIfServices
      ptrpAsrCanIfServicesEcuMIf: provided-interface=itrAsrCanIfServices
      ptrpAsrCanSMServicesBswMIf: provided-interface=itrAsrCanSMServices
      ptrpAsrCanServicesBswMIf: provided-interface=itrAsrCanServices
      ptrpAsrCanServicesEcuMIf: provided-interface=itrAsrCanServices
      ptrpAsrCanTpServicesBswMIf: provided-interface=itrAsrCanTpServices
      ptrpAsrComMServicesBswMIf: provided-interface=itrAsrComMServices
      ptrpAsrComMServicesNmIf: provided-interface=itrAsrComMServices
      ptrpAsrComServicesBswMIf: provided-interface=itrAsrComServices
      ptrpAsrDcmServicesBswMIf: provided-interface=itrAsrDcmServices
      ptrpAsrDemServicesBswMIf: provided-interface=itrAsrDemServices
      ptrpAsrDemServicesEcuMIf: provided-interface=itrAsrDemServices
      ptrpAsrDioServicesDioIf: provided-interface=itrAsrDioServices
      ptrpAsrEcuMServicesBswMIf: provided-interface=itrAsrEcuMServices
      ptrpAsrEcuMServicesEcuMIf: provided-interface=itrAsrEcuMServices
      ptrpAsrEcuMServicesOsIf: provided-interface=itrAsrEcuMServices
      ptrpAsrFeeServicesBswMIf: provided-interface=itrAsrFeeServices
      ptrpAsrFeeServicesEcuMIf: provided-interface=itrAsrFeeServices
      ptrpAsrFlsServicesBswMIf: provided-interface=itrAsrFlsServices
      ptrpAsrFlsServicesEcuMIf: provided-interface=itrAsrFlsServices
      ptrpAsrGptServicesAdcIf: provided-interface=itrAsrGptServices
      ptrpAsrGptServicesBswMIf: provided-interface=itrAsrGptServices
      ptrpAsrNvMServicesBswMIf: provided-interface=itrAsrNvMServices
      ptrpAsrOsServicesBswMIf: provided-interface=itrAsrOsServices
      ptrpAsrPduRServicesBswMIf: provided-interface=itrAsrPduRServices
      ptrpAsrPwmServicesEcuMIf: provided-interface=itrAsrPwmServices
      ptrpAsrPwmServicesPwmIf: provided-interface=itrAsrPwmServices
      ptrpAsrRteServicesBswMIf: provided-interface=itrAsrRteServices
      ptrpAsrSpiServicesEcuMIf: provided-interface=itrAsrSpiServices
      ptrpAsrSpiServicesSpiIf: provided-interface=itrAsrSpiServices
      ptrpMcuServicesEcuMIf: provided-interface=itrAsrMcuServices
    23 x require port:
      ptrrAsrBswMServicesBswMIf: required-interface=itrAsrBswMServices
      ptrrAsrCanServicesEcuMIf: required-interface=itrAsrCanServices
      ptrrAsrComServicesNmIf: required-interface=itrAsrComServices
      ptrrAsrDcmServicesDcmIf: required-interface=itrAsrDcmServices
      ptrrAsrDemServicesDemIf: required-interface=itrAsrDemServices
      ptrrAsrEcuMServicesEcuMIf: required-interface=itrAsrEcuMServices
      ptrrAsrEcuMServicesSbc: required-interface=itrAsrEcuMServices
      ptrrAsrGptServicesAdcIf: required-interface=itrAsrGptServices
      ptrrAsrGptServicesBswMIf: required-interface=itrAsrGptServices
      ptrrAsrNvMServicesBswMIf: required-interface=itrAsrNvMServices
      ptrrAsrOsServicesACC: required-interface=itrAsrOsServices
      ptrrAsrOsServicesATM: required-interface=itrAsrOsServices
      ptrrAsrOsServicesBswMIf: required-interface=itrAsrOsServices
      ptrrAsrOsServicesCIL: required-interface=itrAsrOsServices
      ptrrAsrOsServicesECS: required-interface=itrAsrOsServices
      ptrrAsrOsServicesFSM: required-interface=itrAsrOsServices
      ptrrAsrOsServicesIoHwAb: required-interface=itrAsrOsServices
      ptrrAsrOsServicesLpm: required-interface=itrAsrOsServices
      ptrrAsrOsServicesNmIf: required-interface=itrAsrOsServices
      ptrrAsrOsServicesOsIf: required-interface=itrAsrOsServices
      ptrrAsrOsServicesSAD: required-interface=itrAsrOsServices
      ptrrAsrOsServicesSBC: required-interface=itrAsrOsServices
      ptrrAsrOsServicesSTM: required-interface=itrAsrOsServices
    22 x component:
      Adc: type=Adc
      BswM: type=BswM
      Can: type=Can
      CanIf: type=CanIf
      CanSM: type=CanSM
      CanTp: type=CanTp
      Com: type=Com
      ComM: type=ComM
      Dcm: type=Dcm_
      Dem: type=Dem_
      Dio: type=Dio
      EcuM: type=EcuM
      Fee: type=Fee
      Fls: type=Fls
      Gpt: type=Gpt
      Mcu: type=Mcu
      NvM: type=NvM
      Os: type=Os
      PduR: type=PduR
      Pwm: type=Pwm
      Rte: type=Rte
      Spi: type=Spi
    connectors delegation-sw-connector={inner-port=Adc.ptrpAsrAdcServicesAdcIf, outer-port=ptrpAsrAdcServicesAdcIf}, delegation-sw-connector={inner-port=Adc.ptrpAsrAdcServicesEcuMIf, outer-port=ptrpAsrAdcServicesEcuMIf}, delegation-sw-connector={inner-port=CanIf.ptrpAsrCanIfServicesEcuMIf, outer-port=ptrpAsrCanIfServicesEcuMIf}, delegation-sw-connector={inner-port=Com.ptrrAsrComServicesNmIf, outer-port=ptrrAsrComServicesNmIf}, delegation-sw-connector={inner-port=BswM.ptrrAsrBswMServicesBswMIf, outer-port=S32K_eCS_ECU_Autosar_Interfaces/ptrrAsrBswMServicesBswMIf}, delegation-sw-connector={inner-port=BswM.ptrpAsrBswMServicesBswMIf, outer-port=S32K_eCS_ECU_Autosar_Interfaces/ptrpAsrBswMServicesBswMIf}, delegation-sw-connector={inner-port=BswM.ptrpAsrBswMServicesNmIf, outer-port=ptrpAsrBswMServicesNmIf}, delegation-sw-connector={inner-port=BswM.ptrpAsrBswMServicesOsIf, outer-port=ptrpAsrBswMServicesOsIf}, delegation-sw-connector={inner-port=Can.ptrrAsrCanServicesEcuMIf, outer-port=ptrrAsrComServicesNmIf}, delegation-sw-connector={inner-port=Can.ptrpAsrCanServicesEcuMIf, outer-port=S32K_eCS_ECU_Autosar_Interfaces/ptrpAsrCanServicesEcuMIf}, delegation-sw-connector={inner-port=ComM.ptrpAsrComMServicesNmIf, outer-port=ptrpAsrComMServicesNmIf}, delegation-sw-connector={inner-port=EcuM.ptrrAsrEcuMServicesEcuMIf, outer-port=S32K_eCS_ECU_Autosar_Interfaces/ptrrAsrEcuMServicesEcuMIf}, delegation-sw-connector={inner-port=EcuM.ptrrAsrEcuMServicesSbc, outer-port=ptrrAsrEcuMServicesSbc}, delegation-sw-connector={inner-port=EcuM.ptrpAsrEcuMServicesBswMIf, outer-port=ptrpAsrEcuMServicesBswMIf}, delegation-sw-connector={inner-port=EcuM.ptrpAsrEcuMServicesEcuMIf, outer-port=S32K_eCS_ECU_Autosar_Interfaces/ptrpAsrEcuMServicesEcuMIf}, delegation-sw-connector={inner-port=EcuM.ptrpAsrEcuMServicesOsIf, outer-port=ptrpAsrEcuMServicesOsIf}, delegation-sw-connector={inner-port=Fee.ptrpAsrFeeServicesEcuMIf, outer-port=ptrpAsrFeeServicesEcuMIf}, delegation-sw-connector={inner-port=Fls.ptrpAsrFlsServicesEcuMIf, outer-port=ptrpAsrFlsServicesEcuMIf}, delegation-sw-connector={inner-port=Gpt.ptrrAsrGptServicesAdcIf, outer-port=S32K_eCS_ECU_Autosar_Interfaces/ptrrAsrGptServicesAdcIf}, delegation-sw-connector={inner-port=Gpt.ptrrAsrGptServicesBswMIf, outer-port=S32K_eCS_ECU_Autosar_Interfaces/ptrrAsrGptServicesBswMIf}, delegation-sw-connector={inner-port=Gpt.ptrpAsrGptServicesAdcIf, outer-port=S32K_eCS_ECU_Autosar_Interfaces/ptrpAsrGptServicesAdcIf}, delegation-sw-connector={inner-port=Gpt.ptrpAsrGptServicesBswMIf, outer-port=S32K_eCS_ECU_Autosar_Interfaces/ptrpAsrGptServicesBswMIf}, delegation-sw-connector={inner-port=NvM.ptrrNvMServicesBswMIf, outer-port=S32K_eCS_ECU_Autosar_Interfaces/ptrrAsrNvMServicesBswMIf}, delegation-sw-connector={inner-port=Dcm.ptrrAsrDcmServiceDcmIf, outer-port=ptrrAsrDcmServicesDcmIf}, delegation-sw-connector={inner-port=Os.ptrrAsrOsServicesBswMIf, outer-port=S32K_eCS_ECU_Autosar_Interfaces/ptrrAsrOsServicesBswMIf}, delegation-sw-connector={inner-port=Os.ptrrAsrOsServicesIoHwAb, outer-port=ptrrAsrOsServicesIoHwAb}, delegation-sw-connector={inner-port=Os.ptrrAsrOsServicesLpm, outer-port=ptrrAsrOsServicesLpm}, delegation-sw-connector={inner-port=Os.ptrrAsrOsServicesNmIf, outer-port=ptrrAsrOsServicesNmIf}, delegation-sw-connector={inner-port=Pwm.ptrpAsrPwmServicesEcuMIf, outer-port=ptrpAsrPwmServicesEcuMIf}, delegation-sw-connector={inner-port=Pwm.ptrpAsrPwmServicesPwmIf, outer-port=ptrpAsrPwmServicesPwmIf}, delegation-sw-connector={inner-port=Spi.ptrpAsrSpiServicesEcuMIf, outer-port=ptrpAsrSpiServicesEcuMIf}, delegation-sw-connector={inner-port=Spi.ptrpAsrSpiServicesSpiIf, outer-port=ptrpAsrSpiServicesSpiIf}, delegation-sw-connector={inner-port=Dem.ptrrAsrDemServicesDemIf, outer-port=ptrrAsrDemServicesDemIf}, delegation-sw-connector={inner-port=Dem.ptrpAsrDemServicesEcuMIf, outer-port=ptrpAsrDemServicesEcuMIf}:
      delegate CanIf.ptrpAsrCanIfServicesBswMIf <-> outer port ptrpAsrCanIfServicesBswMIf
      delegate Dcm.ptrpAsrDcmServicesBswMIf <-> outer port ptrpAsrDcmServicesBswMIf
      delegate Dem.ptrpAsrDemServicesBswMIf <-> outer port ptrpAsrDemServicesBswMIf
      delegate Dio.ptrpAsrDioServicesDioIf <-> outer port ptrpAsrDioServicesDioIf
      delegate Fee.ptrpAsrFeeServicesBswMIf <-> outer port ptrpAsrFeeServicesBswMIf
      delegate Fls.ptrpAsrFlsServicesBswMIf <-> outer port ptrpAsrFlsServicesBswMIf
      delegate Mcu.ptrpMcuServicesEcuMIf <-> outer port ptrpMcuServicesEcuMIf
      delegate Os.ptrpAsrOsServicesBswMIf <-> outer port S32K_eCS_ECU_Autosar_Interfaces/ptrpAsrOsServicesBswMIf
      delegate Rte.ptrpAsrRteServicesBswMIf <-> outer port ptrpAsrRteServicesBswMIf
      delegate CanSM.ptrpAsrCanSMServicesBswMIf <-> outer port ptrpAsrCanSMServicesBswMIf
      delegate CanTp.ptrpAsrCanTpServicesBswMIf <-> outer port ptrpAsrCanTpServicesBswMIf
      delegate Com.ptrpAsrComServicesBswMIf <-> outer port ptrpAsrComServicesBswMIf
      delegate NvM.ptrpAsrNvMServicesBswMIf <-> outer port S32K_eCS_ECU_Autosar_Interfaces/ptrpAsrNvMServicesBswMIf
      delegate PduR.ptrpAsrPduRServicesBswMIf <-> outer port ptrpAsrPduRServicesBswMIf
      delegate Can.ptrpAsrCanServicesBswMIf <-> outer port ptrpAsrCanServicesBswMIf
      delegate ComM.ptrpAsrComMServicesBswMIf <-> outer port ptrpAsrComMServicesBswMIf
      delegate Os.ptrrAsrOsServicesACC <-> outer port ptrrAsrOsServicesACC
      delegate Os.ptrrAsrOsServicesATM <-> outer port ptrrAsrOsServicesATM
      delegate Os.ptrrAsrOsServicesFSM <-> outer port ptrrAsrOsServicesFSM
      delegate Os.ptrrAsrOsServicesOsIf <-> outer port ptrrAsrOsServicesOsIf
      delegate Os.ptrrAsrOsServicesSAD <-> outer port ptrrAsrOsServicesSAD
      delegate Os.ptrrAsrOsServicesSBC <-> outer port ptrrAsrOsServicesSBC
      delegate Os.ptrrAsrOsServicesSTM <-> outer port ptrrAsrOsServicesSTM
      delegate Os.ptrrAsrOsServicesECS <-> outer port ptrrAsrOsServicesECS
      delegate Os.ptrrAsrOsServicesCIL <-> outer port ptrrAsrOsServicesCIL
